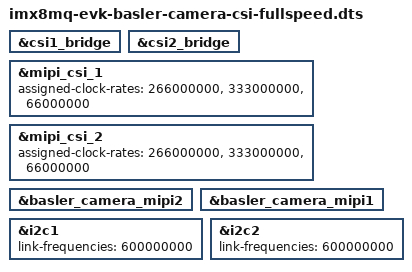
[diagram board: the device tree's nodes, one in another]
#include "imx8mq-evk.dts"
#include "imx8mq-evk-basler-camera-csi.dtsi"

&csi1_bridge {
	status = "okay";
};

&csi2_bridge {
	status = "okay";
};

&mipi_csi_1 {
	status = "okay";
	assigned-clock-rates = <266000000>, <333000000>, <66000000>;
};

&mipi_csi_2 {
	status = "okay";
	assigned-clock-rates = <266000000>, <333000000>, <66000000>;
};

&basler_camera_mipi2 {
	status = "okay";
};

&basler_camera_mipi1 {
	status = "okay";
};

&i2c1 {
	link-frequencies = /bits/ 64 <600000000>;
};

&i2c2 {
	link-frequencies = /bits/ 64 <600000000>;
};
